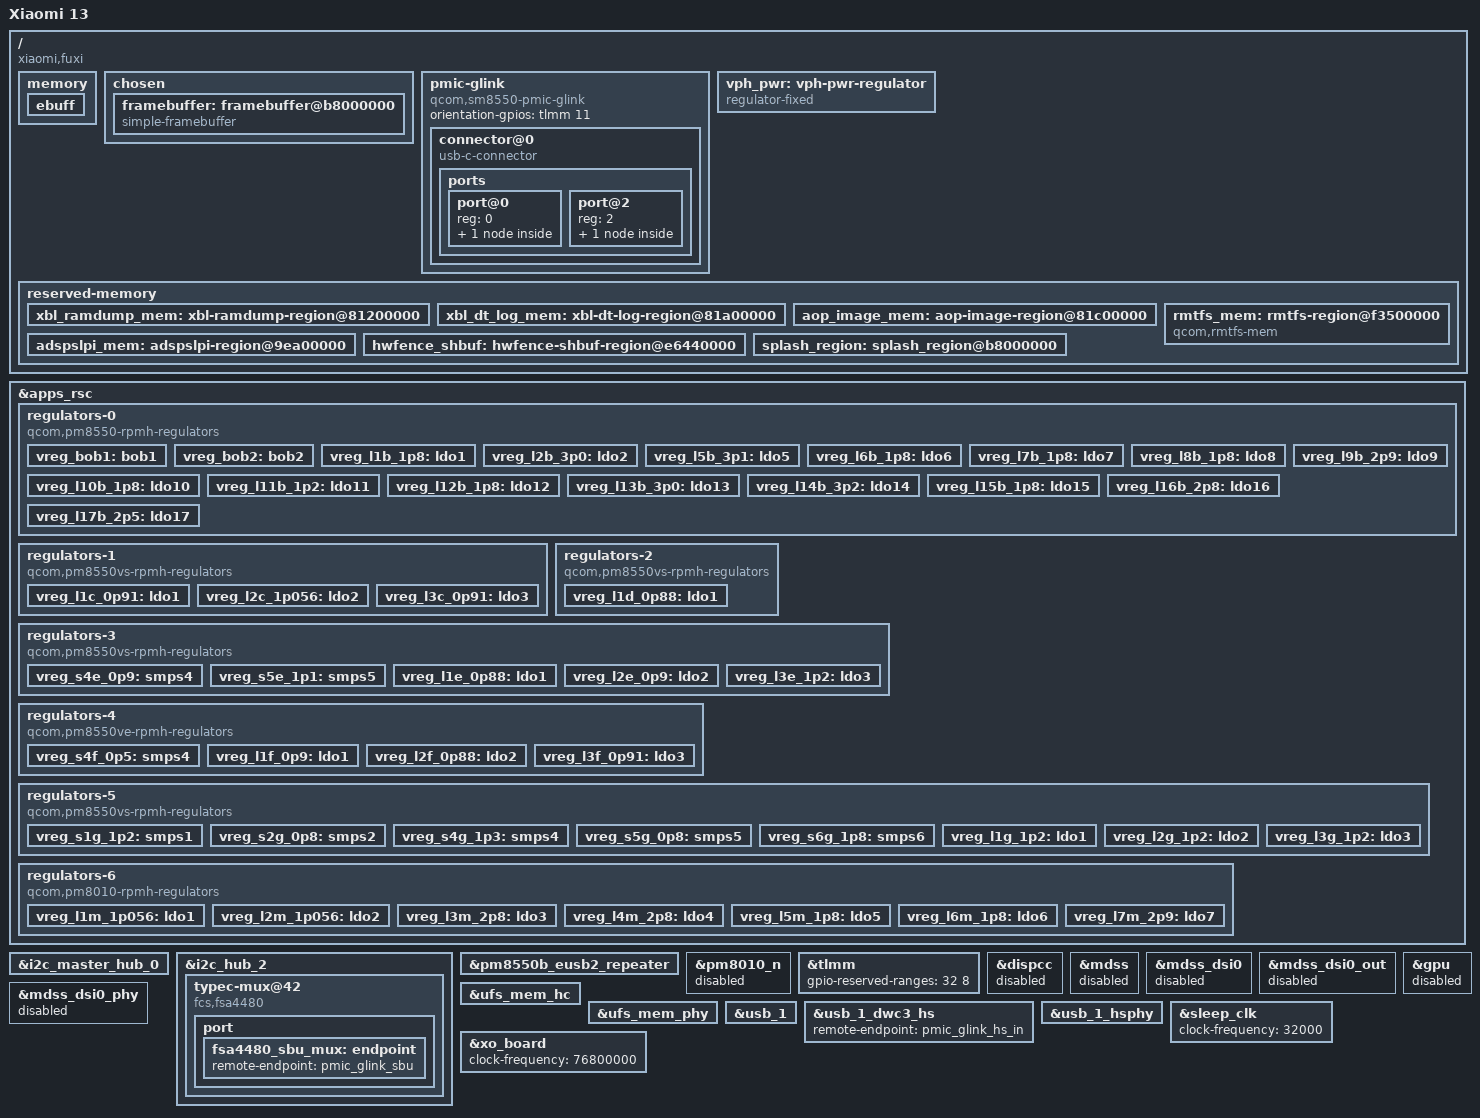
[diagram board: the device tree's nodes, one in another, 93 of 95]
// SPDX-License-Identifier: GPL-2.0-only

/dts-v1/;

#include <dt-bindings/regulator/qcom,rpmh-regulator.h>
#include "sm8550.dtsi"
#include "pm8010.dtsi"
#include "pm8550.dtsi"
#include "pm8550b.dtsi"
#define PMK8550VE_SID 5
#include "pm8550ve.dtsi"
#include "pm8550vs.dtsi"
#include "pmk8550.dtsi"

/delete-node/ &rmtfs_mem;
/delete-node/ &adspslpi_mem;
/delete-node/ &xbl_dt_log_merged_mem;
/delete-node/ &hwfence_shbuf;

/*
 * Free unused regions, these regions don't exist in downstream
 * dts, and they aren't removed from DDR Memory Map by UEFI.
 */
/delete-node/ &hyp_tags_reserved_mem;
/delete-node/ &cdsp_secure_heap_mem;
/delete-node/ &trust_ui_vm_mem;
/delete-node/ &trust_ui_vm_dump;
/delete-node/ &trust_ui_vm_qrtr;
/delete-node/ &trust_ui_vm_vblk0_ring;
/delete-node/ &trust_ui_vm_vblk1_ring;
/delete-node/ &trust_ui_vm_swiotlb;
/delete-node/ &oem_vm_vblk0_ring;
/delete-node/ &oem_vm_swiotlb;
/delete-node/ &oem_vm_mem;
/delete-node/ &hyp_ext_tags_mem;
/delete-node/ &hyp_ext_reserved_mem;

/ {
	model = "Xiaomi 13";
	compatible = "xiaomi,fuxi", "qcom,sm8550";
	chassis-type = "handset";
	qcom,msm-id = <0x207 0x20000 0x218 0x20000>;
	qcom,board-id = <0x10008 0>;

	memory {
		ddr_manufacturer_id = <0xff>;
		ddr_device_type = <0x08>;
		ufs_ffu_batterystatus = <0x00>;
		ufs_ffu_bootreason = <0x01>;
		ddr_size = <0x0c>;
		device_type = "memory";
		reg = <0x00 0x80000000 0x00 0xe00000 0x00 0x811d0000 0x00 0x56e30000 0x00 0xd8140000 0x00 0x20000 0x00 0xd8800000 0x00 0x00 0x00 0xe7cb0000 0x00 0x18350000 0x08 0x80000000 0x00 0x39d00000 0x08 0xc0000000 0x00 0xc0000000 0x09 0x80000000 0x01 0x80000000 0x08 0xb9f00000 0x00 0x1e00000>;

		ebuff {
		};
	};
	
	chosen {
		#address-cells = <2>;
		#size-cells = <2>;
		ranges;

		bootargs = "keep_bootcon rootwait clk_ignore_unused pd_ignore_unused ignore_loglevel console=tty0 pmos.debug-shell PMOS_NOSPLASH"; //earlycon=simplefb,0xb8000000,1080,2400 initcall_debug clk_ignore_unused pd_ignore_unused
		
		framebuffer: framebuffer@b8000000 {
			compatible = "simple-framebuffer";
			reg = <0x0 0xb8000000 0x0 0x2b00000>;
			width = <1080>;
			height = <2400>;
			stride = <(1080 * 4)>;
			format = "a8r8g8b8";

			clocks = <&gcc GCC_DISP_AHB_CLK>, <&gcc GCC_DISP_HF_AXI_CLK>;
		};
	};

	pmic-glink {
		compatible = "qcom,sm8550-pmic-glink", "qcom,pmic-glink";
		#address-cells = <1>;
		#size-cells = <0>;
		orientation-gpios = <&tlmm 11 GPIO_ACTIVE_HIGH>;

		connector@0 {
			compatible = "usb-c-connector";
			reg = <0>;
			power-role = "dual";
			data-role = "dual";

			ports {
				#address-cells = <1>;
				#size-cells = <0>;

				port@0 {
					reg = <0>;

					pmic_glink_hs_in: endpoint {
						remote-endpoint = <&usb_1_dwc3_hs>;
					};
				};
				/*
				port@1 {
					reg = <1>;

					pmic_glink_ss_in: endpoint {
						remote-endpoint = <&usb_dp_qmpphy_out>;
					};
				};
				*/
				port@2 {
					reg = <2>;

					pmic_glink_sbu: endpoint {
						remote-endpoint = <&fsa4480_sbu_mux>;
					};
				};
				
			};
		};
	};
	
	vph_pwr: vph-pwr-regulator {
		compatible = "regulator-fixed";
		regulator-name = "vph_pwr";
		regulator-min-microvolt = <3700000>;
		regulator-max-microvolt = <3700000>;
		regulator-always-on;
		regulator-boot-on;
	};

	reserved-memory {
		xbl_ramdump_mem: xbl-ramdump-region@81200000 {
			reg = <0 0x81200000 0 0x280000>;
			no-map;
		};

		xbl_dt_log_mem: xbl-dt-log-region@81a00000 {
			reg = <0 0x81a00000 0 0x40000>;
			no-map;
		};

		aop_image_mem: aop-image-region@81c00000 {
			reg = <0 0x81c00000 0 0x60000>;
			no-map;
		};
		adspslpi_mem: adspslpi-region@9ea00000 {
			reg = <0 0x9ea00000 0 0x4680000>;
			no-map;
		};

		rmtfs_mem: rmtfs-region@f3500000 {
			compatible = "qcom,rmtfs-mem";
			reg = <0x0 0xf3500000 0x0 0x280000>;
			no-map;

			qcom,client-id = <1>;
			qcom,vmid = <QCOM_SCM_VMID_MSS_MSA>;
		};

		hwfence_shbuf: hwfence-shbuf-region@e6440000 {
			reg = <0 0xe6440000 0 0x2dd000>;
			no-map;
		};

		splash_region: splash_region@b8000000 {
			reg = <0x0 0xb8000000 0x0 0x2b00000>;
			no-map;
		};
	};
};

&apps_rsc {
	regulators-0 {
		compatible = "qcom,pm8550-rpmh-regulators";
		qcom,pmic-id = "b";

		vdd-bob1-supply = <&vph_pwr>;
		vdd-bob2-supply = <&vph_pwr>;
		vdd-l1-l4-l10-supply = <&vreg_s6g_1p8>;
		vdd-l2-l13-l14-supply = <&vreg_bob1>;
		vdd-l3-supply = <&vreg_s4g_1p3>;
		vdd-l5-l16-supply = <&vreg_bob1>;
		vdd-l6-l7-supply = <&vreg_bob1>;
		vdd-l8-l9-supply = <&vreg_bob1>;
		vdd-l11-supply = <&vreg_s4g_1p3>;
		vdd-l12-supply = <&vreg_s6g_1p8>;
		vdd-l15-supply = <&vreg_s6g_1p8>;
		vdd-l17-supply = <&vreg_bob2>;

		vreg_bob1: bob1 {
			regulator-name = "vreg_bob1";
			regulator-min-microvolt = <3008000>;
			regulator-max-microvolt = <3960000>;
			regulator-initial-mode = <RPMH_REGULATOR_MODE_HPM>;
		};
		
		/* Xiaomi change for Camera Modules */
		vreg_bob2: bob2 {
			regulator-name = "vreg_bob2";
			regulator-min-microvolt = <2704000>;
			regulator-max-microvolt = <3104000>;
			regulator-initial-mode = <RPMH_REGULATOR_MODE_HPM>;
		};

		vreg_l1b_1p8: ldo1 {
			regulator-name = "vreg_l1b_1p8";
			regulator-min-microvolt = <1800000>;
			regulator-max-microvolt = <1800000>;
			regulator-initial-mode = <RPMH_REGULATOR_MODE_HPM>;
		};

		vreg_l2b_3p0: ldo2 {
			regulator-name = "vreg_l2b_3p0";
			regulator-min-microvolt = <3008000>;
			regulator-max-microvolt = <3008000>;
			regulator-initial-mode = <RPMH_REGULATOR_MODE_HPM>;
		};

		vreg_l5b_3p1: ldo5 {
			regulator-name = "vreg_l5b_3p1";
			regulator-min-microvolt = <3104000>;
			regulator-max-microvolt = <3104000>;
			regulator-initial-mode = <RPMH_REGULATOR_MODE_HPM>;
		};

		vreg_l6b_1p8: ldo6 {
			regulator-name = "vreg_l6b_1p8";
			regulator-min-microvolt = <1800000>;
			regulator-max-microvolt = <3008000>;
			regulator-initial-mode = <RPMH_REGULATOR_MODE_HPM>;
		};

		vreg_l7b_1p8: ldo7 {
			regulator-name = "vreg_l7b_1p8";
			regulator-min-microvolt = <1800000>;
			regulator-max-microvolt = <3008000>;
			regulator-initial-mode = <RPMH_REGULATOR_MODE_HPM>;
		};

		vreg_l8b_1p8: ldo8 {
			regulator-name = "vreg_l8b_1p8";
			regulator-min-microvolt = <1800000>;
			regulator-max-microvolt = <3008000>;
			regulator-initial-mode = <RPMH_REGULATOR_MODE_HPM>;
			regulator-always-on;
			regulator-boot-on;
		};

		vreg_l9b_2p9: ldo9 {
			regulator-name = "vreg_l9b_2p9";
			regulator-min-microvolt = <3200000>;
			regulator-max-microvolt = <3200000>;
			regulator-initial-mode = <RPMH_REGULATOR_MODE_HPM>;
		};

		vreg_l10b_1p8: ldo10 {
			regulator-name = "vreg_l10b_1p8";
			regulator-min-microvolt = <1800000>;
			regulator-max-microvolt = <1800000>;
			regulator-initial-mode = <RPMH_REGULATOR_MODE_HPM>;
			regulator-always-on;
		};

		vreg_l11b_1p2: ldo11 {
			regulator-name = "vreg_l11b_1p2";
			regulator-min-microvolt = <1056000>;
			regulator-max-microvolt = <1056000>;
			regulator-initial-mode = <RPMH_REGULATOR_MODE_HPM>;
		};

		vreg_l12b_1p8: ldo12 {
			regulator-name = "vreg_l12b_1p8";
			regulator-min-microvolt = <1800000>;
			regulator-max-microvolt = <1800000>;
			regulator-initial-mode = <RPMH_REGULATOR_MODE_HPM>;
		};

		vreg_l13b_3p0: ldo13 {
			regulator-name = "vreg_l13b_3p0";
			regulator-min-microvolt = <3000000>;
			regulator-max-microvolt = <3000000>;
			regulator-initial-mode = <RPMH_REGULATOR_MODE_HPM>;
		};

		/* Xiaomi change for Camera Modules */
		vreg_l14b_3p2: ldo14 {
			regulator-name = "vreg_l14b_3p2";
			regulator-min-microvolt = <3104000>;
			regulator-max-microvolt = <3104000>;
			regulator-initial-mode = <RPMH_REGULATOR_MODE_HPM>;
		};

		vreg_l15b_1p8: ldo15 {
			regulator-name = "vreg_l15b_1p8";
			regulator-min-microvolt = <1800000>;
			regulator-max-microvolt = <1800000>;
			regulator-initial-mode = <RPMH_REGULATOR_MODE_HPM>;
			regulator-always-on;
		};

		/* Xiaomi change for Camera Modules */
		vreg_l16b_2p8: ldo16 {
			regulator-name = "vreg_l16b_2p8";
			regulator-min-microvolt = <3104000>;
			regulator-max-microvolt = <3104000>;
			regulator-initial-mode = <RPMH_REGULATOR_MODE_HPM>;
		};

		vreg_l17b_2p5: ldo17 {
			regulator-name = "vreg_l17b_2p5";
			regulator-min-microvolt = <2504000>;
			regulator-max-microvolt = <2504000>;
			regulator-initial-mode = <RPMH_REGULATOR_MODE_HPM>;
		};
	};

	regulators-1 {
		compatible = "qcom,pm8550vs-rpmh-regulators";
		qcom,pmic-id = "c";

		vdd-l3-supply = <&vreg_s4e_0p9>;

		vreg_l1c_0p91: ldo1 {
			regulator-name = "vreg_l1c_0p9";
			regulator-min-microvolt = <1200000>;
			regulator-max-microvolt = <1200000>;
			regulator-initial-mode = <RPMH_REGULATOR_MODE_HPM>;
		};

		vreg_l2c_1p056: ldo2 {
			regulator-name = "vreg_l2c_0p1056";
			regulator-min-microvolt = <1800000>;
			regulator-max-microvolt = <1800000>;
			regulator-initial-mode = <RPMH_REGULATOR_MODE_HPM>;
		};

		vreg_l3c_0p91: ldo3 {
			regulator-name = "vreg_l3c_0p9";
			regulator-min-microvolt = <880000>;
			regulator-max-microvolt = <912000>;
			regulator-initial-mode = <RPMH_REGULATOR_MODE_HPM>;
		};
	};

	regulators-2 {
		compatible = "qcom,pm8550vs-rpmh-regulators";
		qcom,pmic-id = "d";

		vdd-l1-supply = <&vreg_s4e_0p9>;

		vreg_l1d_0p88: ldo1 {
			regulator-name = "vreg_l1d_0p88";
			regulator-min-microvolt = <912000>;
			regulator-max-microvolt = <920000>;
			regulator-initial-mode = <RPMH_REGULATOR_MODE_HPM>;
		};
	};

	regulators-3 {
		compatible = "qcom,pm8550vs-rpmh-regulators";
		qcom,pmic-id = "e";

		vdd-l1-supply = <&vreg_s4e_0p9>;
		vdd-l2-supply = <&vreg_s4e_0p9>;
		vdd-l3-supply = <&vreg_s4g_1p3>;
		vdd-s4-supply = <&vph_pwr>;
		vdd-s5-supply = <&vph_pwr>;

		vreg_s4e_0p9: smps4 {
			regulator-name = "vreg_s4e_0p9";
			regulator-min-microvolt = <904000>;
			regulator-max-microvolt = <984000>;
			regulator-initial-mode = <RPMH_REGULATOR_MODE_HPM>;
		};

		vreg_s5e_1p1: smps5 {
			regulator-name = "vreg_s5e_1p1";
			regulator-min-microvolt = <1010000>;
			regulator-max-microvolt = <1120000>;
			regulator-initial-mode = <RPMH_REGULATOR_MODE_HPM>;
		};

		vreg_l1e_0p88: ldo1 {
			regulator-name = "vreg_l1e_0p88";
			regulator-min-microvolt = <880000>;
			regulator-max-microvolt = <912000>;
			regulator-initial-mode = <RPMH_REGULATOR_MODE_HPM>;
			regulator-always-on;
		};

		vreg_l2e_0p9: ldo2 {
			regulator-name = "vreg_l2e_0p9";
			regulator-min-microvolt = <872000>;
			regulator-max-microvolt = <972000>;
			regulator-initial-mode = <RPMH_REGULATOR_MODE_HPM>;
		};

		vreg_l3e_1p2: ldo3 {
			regulator-name = "vreg_l3e_1p2";
			regulator-min-microvolt = <1200000>;
			regulator-max-microvolt = <1200000>;
			regulator-initial-mode = <RPMH_REGULATOR_MODE_HPM>;
			regulator-always-on;
		};
	};

	regulators-4 {
		compatible = "qcom,pm8550ve-rpmh-regulators";
		qcom,pmic-id = "f";

		vdd-l1-supply = <&vreg_s4e_0p9>;
		vdd-l2-supply = <&vreg_s4e_0p9>;
		vdd-l3-supply = <&vreg_s4e_0p9>;
		vdd-s4-supply = <&vph_pwr>;

		vreg_s4f_0p5: smps4 {
			regulator-name = "vreg_s4f_0p5";
			regulator-min-microvolt = <300000>;
			regulator-max-microvolt = <700000>;
			regulator-initial-mode = <RPMH_REGULATOR_MODE_HPM>;
		};

		vreg_l1f_0p9: ldo1 {
			regulator-name = "vreg_l1f_0p9";
			regulator-min-microvolt = <880000>;
			regulator-max-microvolt = <912000>;
			regulator-initial-mode = <RPMH_REGULATOR_MODE_HPM>;
		};

		vreg_l2f_0p88: ldo2 {
			regulator-name = "vreg_l2f_0p88";
			regulator-min-microvolt = <880000>;
			regulator-max-microvolt = <912000>;
			regulator-initial-mode = <RPMH_REGULATOR_MODE_HPM>;
		};

		vreg_l3f_0p91: ldo3 {
			regulator-name = "vreg_l3f_0p91";
			regulator-min-microvolt = <880000>;
			regulator-max-microvolt = <912000>;
			regulator-initial-mode = <RPMH_REGULATOR_MODE_HPM>;
			regulator-always-on;
		};
	};

	regulators-5 {
		compatible = "qcom,pm8550vs-rpmh-regulators";
		qcom,pmic-id = "g";

		vdd-l1-supply = <&vreg_s4g_1p3>;
		vdd-l2-supply = <&vreg_s4g_1p3>;
		vdd-l3-supply = <&vreg_s4g_1p3>;
		vdd-s1-supply = <&vph_pwr>;
		vdd-s2-supply = <&vph_pwr>;
		vdd-s3-supply = <&vph_pwr>;
		vdd-s4-supply = <&vph_pwr>;
		vdd-s5-supply = <&vph_pwr>;
		vdd-s6-supply = <&vph_pwr>;

		vreg_s1g_1p2: smps1 {
			regulator-name = "vreg_s1g_1p2";
			regulator-min-microvolt = <1200000>;
			regulator-max-microvolt = <1300000>;
			regulator-initial-mode = <RPMH_REGULATOR_MODE_HPM>;
		};

		vreg_s2g_0p8: smps2 {
			regulator-name = "vreg_s2g_0p8";
			regulator-min-microvolt = <500000>;
			regulator-max-microvolt = <1036000>;
			regulator-initial-mode = <RPMH_REGULATOR_MODE_HPM>;
		};

		vreg_s4g_1p3: smps4 {
			regulator-name = "vreg_s4g_1p3";
			regulator-min-microvolt = <1200000>;
			regulator-max-microvolt = <1352000>;
			regulator-initial-mode = <RPMH_REGULATOR_MODE_HPM>;
		};

		vreg_s5g_0p8: smps5 {
			regulator-name = "vreg_s5g_0p8";
			regulator-min-microvolt = <500000>;
			regulator-max-microvolt = <1004000>;
			regulator-initial-mode = <RPMH_REGULATOR_MODE_HPM>;
		};

		vreg_s6g_1p8: smps6 {
			regulator-name = "vreg_s6g_1p8";
			regulator-min-microvolt = <1800000>;
			regulator-max-microvolt = <2000000>;
			regulator-initial-mode = <RPMH_REGULATOR_MODE_HPM>;
		};

		vreg_l1g_1p2: ldo1 {
			regulator-name = "vreg_l1g_1p2";
			regulator-min-microvolt = <1144000>;
			regulator-max-microvolt = <1256000>;
			regulator-initial-mode = <RPMH_REGULATOR_MODE_HPM>;
		};

		vreg_l2g_1p2: ldo2 {
			regulator-name = "vreg_l2g_1p2";
			regulator-min-microvolt = <1100000>;
			regulator-max-microvolt = <1200000>;
			regulator-initial-mode = <RPMH_REGULATOR_MODE_HPM>;
		};

		vreg_l3g_1p2: ldo3 {
			regulator-name = "vreg_l3g_1p2";
			regulator-min-microvolt = <1200000>;
			regulator-max-microvolt = <1200000>;
			regulator-initial-mode = <RPMH_REGULATOR_MODE_HPM>;
		};
	};

	regulators-6 {
		compatible = "qcom,pm8010-rpmh-regulators";
		qcom,pmic-id = "m";

		vdd-l1-l2-supply = <&vreg_s4g_1p3>;
		vdd-l3-l4-supply = <&vreg_bob2>;
		vdd-l5-supply = <&vreg_s6g_1p8>;
		vdd-l6-supply = <&vreg_s6g_1p8>;
		vdd-l7-supply = <&vreg_bob1>;

		/* Xiaomi change for Camera Modules */
		vreg_l1m_1p056: ldo1 {
			regulator-name = "vreg_l1m_1p056";
			regulator-min-microvolt = <1104000>;
			regulator-max-microvolt = <1104000>;
			regulator-initial-mode = <RPMH_REGULATOR_MODE_HPM>;
		};

		vreg_l2m_1p056: ldo2 {
			regulator-name = "vreg_l2m_1p056";
			regulator-min-microvolt = <1104000>;
			regulator-max-microvolt = <1104000>;
			regulator-initial-mode = <RPMH_REGULATOR_MODE_HPM>;
		};

		vreg_l3m_2p8: ldo3 {
			regulator-name = "vreg_l3m_2p8";
			regulator-min-microvolt = <2800000>;
			regulator-max-microvolt = <2800000>;
			regulator-initial-mode = <RPMH_REGULATOR_MODE_HPM>;
		};

		vreg_l4m_2p8: ldo4 {
			regulator-name = "vreg_l4m_2p8";
			regulator-min-microvolt = <3104000>;
			regulator-max-microvolt = <3104000>;
			regulator-initial-mode = <RPMH_REGULATOR_MODE_HPM>;
		};

		vreg_l5m_1p8: ldo5 {
			regulator-name = "vreg_l5m_1p8";
			regulator-min-microvolt = <1800000>;
			regulator-max-microvolt = <1800000>;
			regulator-initial-mode = <RPMH_REGULATOR_MODE_HPM>;
		};

		/* Xiaomi change for Camera Modules */
		vreg_l6m_1p8: ldo6 {
			regulator-name = "vreg_l6m_1p8";
			regulator-min-microvolt = <1800000>;
			regulator-max-microvolt = <3200000>;
			regulator-initial-mode = <RPMH_REGULATOR_MODE_HPM>;
		};

		vreg_l7m_2p9: ldo7 {
			regulator-name = "vreg_l7m_2p9";
			regulator-min-microvolt = <3104000>;
			regulator-max-microvolt = <3104000>;
			regulator-initial-mode = <RPMH_REGULATOR_MODE_HPM>;
		};
	};
};

&i2c_master_hub_0 {
	status = "okay";
};

&i2c_hub_2 {
	status = "okay";

	typec-mux@42 {
		compatible = "fcs,fsa4480";
		reg = <0x42>;

		vcc-supply = <&vreg_bob1>;

		mode-switch;
		orientation-switch;

		port {
			fsa4480_sbu_mux: endpoint {
				remote-endpoint = <&pmic_glink_sbu>;
			};
		};
	};
};

&pm8550b_eusb2_repeater {
	vdd18-supply = <&vreg_l15b_1p8>;
	vdd3-supply = <&vreg_l5b_3p1>;
};

&pm8010_n {
	status = "disabled";
};

&tlmm {
    gpio-reserved-ranges = <32 8>;
};

&dispcc {
    status = "disabled";
};

&mdss {
    status = "disabled";
};

&mdss_dsi0 {
    status = "disabled";
};

&mdss_dsi0_out {
    status = "disabled";
};

&mdss_dsi0_phy {
    status = "disabled";
};

&gpu {
    status = "disabled";
};

&ufs_mem_hc {
	reset-gpios = <&tlmm 210 GPIO_ACTIVE_LOW>;
	vcc-supply = <&vreg_l17b_2p5>;
	vcc-max-microamp = <1300000>;
	vccq-supply = <&vreg_l1g_1p2>;
	vccq-max-microamp = <1200000>;
	vdd-hba-supply = <&vreg_l3g_1p2>;

	status = "okay";
};

&ufs_mem_phy {
	vdda-phy-supply = <&vreg_l1d_0p88>;
	vdda-pll-supply = <&vreg_l3e_1p2>;

	status = "okay";
};

&usb_1 {
	status = "okay";
};

&usb_1_dwc3_hs {
	remote-endpoint = <&pmic_glink_hs_in>;
};

&usb_1_hsphy {
	vdd-supply = <&vreg_l1e_0p88>;
	vdda12-supply = <&vreg_l3e_1p2>;

	phys = <&pm8550b_eusb2_repeater>;

	status = "okay";
};
/*
&usb_dp_qmpphy {
	vdda-phy-supply = <&vreg_l3e_1p2>;
	vdda-pll-supply = <&vreg_l3f_0p91>;

	status = "okay";
};

&usb_dp_qmpphy_out {
	remote-endpoint = <&pmic_glink_ss_in>;
};
*/
&sleep_clk {
	clock-frequency = <32000>;
};

&xo_board {
	clock-frequency = <76800000>;
};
